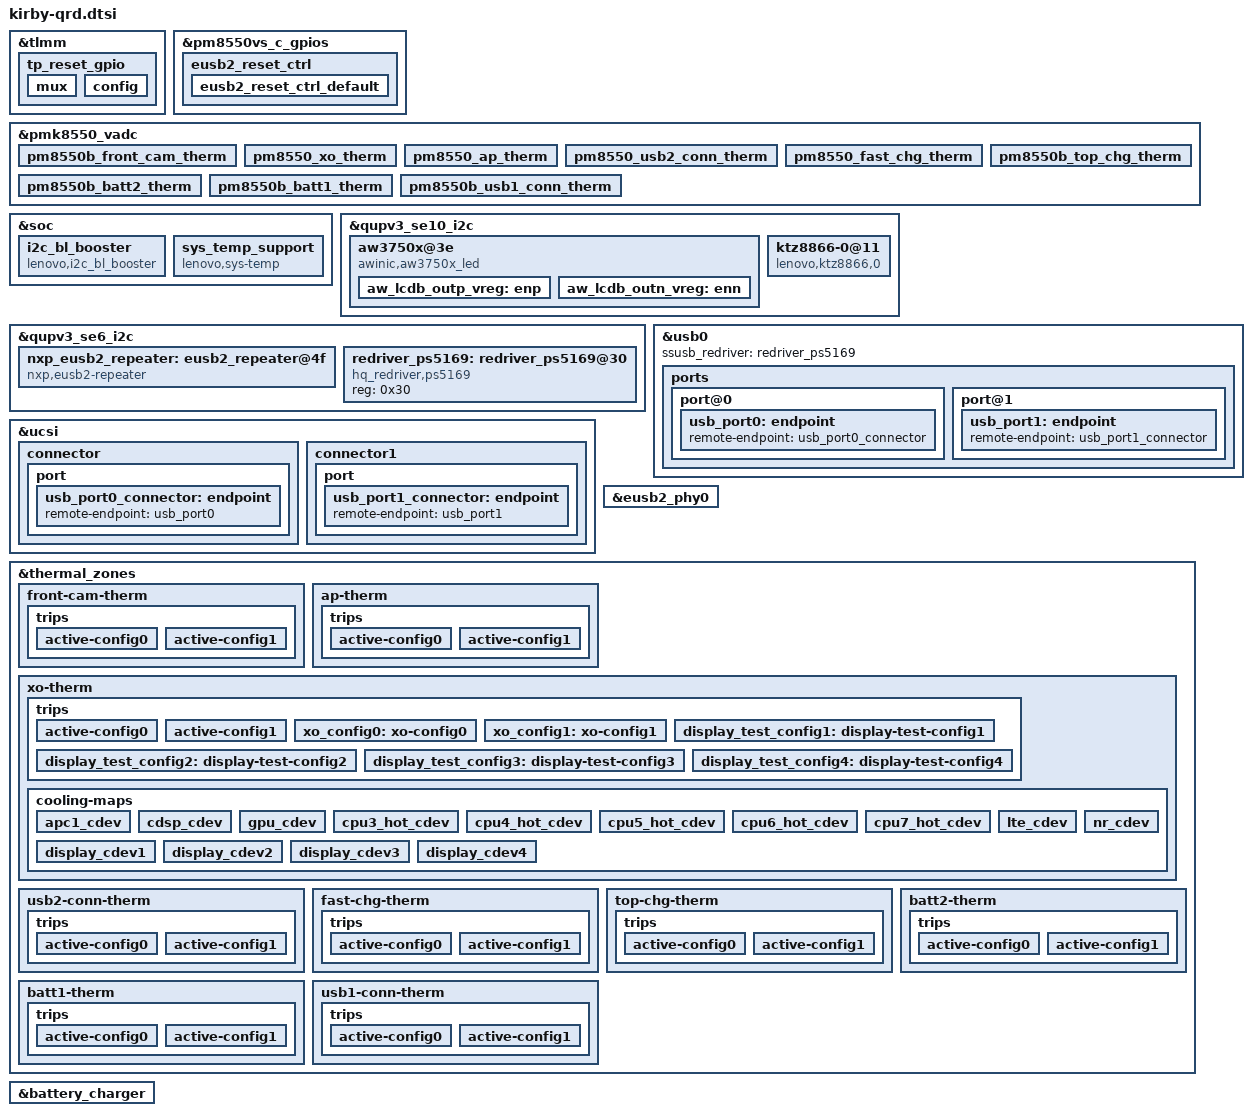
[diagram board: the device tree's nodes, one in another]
#include "pineapple-qrd.dtsi"
#include "kirby-touch-novatek.dtsi"

&tlmm {
	tp_reset_gpio: tp_reset_gpio {
		mux {
			pins = "gpio161";
			function = "gpio";
		};

		config {
			pins = "gpio161";
			bias-pull-up;
		};
	};
};

&pm8550vs_c_gpios {
	eusb2_reset_ctrl {
		eusb2_reset_ctrl_default: eusb2_reset_ctrl_default {
			pins = "gpio4";
			function = "normal";
			input-enable;
			output-enable;
			bias-disable;
			power-source = <1>;
			qcom,drive-strength = <2>;
		};
	};
};

&pmk8550_vadc {
	pm8550b_front_cam_therm {
		reg = <0x74c>;
		label = "pm8550b_front_cam_therm";
		qcom,ratiometric;
		qcom,hw-settle-time = <200>;
		qcom,pre-scaling = <1 1>;
		qcom,adc-tm-type = <1>;
	};

	pm8550_xo_therm {
		reg = <0x14a>;
		label = "pm8550_xo_therm";
		qcom,ratiometric;
		qcom,hw-settle-time = <200>;
		qcom,pre-scaling = <1 1>;
		qcom,adc-tm-type = <1>;
	};

	pm8550_ap_therm {
		reg = <0x144>;
		label = "pm8550_ap_therm";
		qcom,ratiometric;
		qcom,hw-settle-time = <200>;
		qcom,pre-scaling = <1 1>;
		qcom,adc-tm-type = <1>;
	};

	pm8550_usb2_conn_therm {
		reg = <0x147>;
		label = "pm8550_usb2_conn_therm";
		qcom,ratiometric;
		qcom,hw-settle-time = <200>;
		qcom,pre-scaling = <1 1>;
		qcom,adc-tm-type = <1>;
	};

	pm8550_fast_chg_therm {
		reg = <0x14d>;
		label = "pm8550_fast_chg_therm";
		qcom,ratiometric;
		qcom,hw-settle-time = <200>;
		qcom,pre-scaling = <1 1>;
		qcom,adc-tm-type = <1>;
	};

	pm8550b_top_chg_therm {
		reg = <0x749>;
		label = "pm8550b_top_chg_therm";
		qcom,ratiometric;
		qcom,pre-scaling = <1 1>;
		qcom,adc-tm-type = <1>;
	};

	pm8550b_batt2_therm {
		reg = <0x74d>;
		label = "pm8550b_batt2_therm";
		qcom,ratiometric;
		qcom,pre-scaling = <1 1>;
		qcom,adc-tm-type = <1>;
	};

	pm8550b_batt1_therm {
		reg = <0x744>;
		label = "pm8550b_batt1_therm";
		qcom,ratiometric;
		qcom,pre-scaling = <1 1>;
		qcom,adc-tm-type = <1>;
	};

	pm8550b_usb1_conn_therm {
		reg = <0x747>;
		label = "pm8550b_usb1_conn_therm";
		qcom,ratiometric;
		qcom,pre-scaling = <1 1>;
		qcom,adc-tm-type = <1>;
	};
};

&soc {
	i2c_bl_booster {
		compatible = "lenovo,i2c_bl_booster";
		num-dev = <1>;
		part-number = "ktz8866";
		bl-bw = [00 0b];
		bl-min-lvl = [00 00];
		bl-max-lvl = [07 ff];
		bl-def-lvl = [04 03];
		bl-lsb-mask = [0f];
		bl-msb-mask = [ff];
		status = "ok";
	};

	sys_temp_support {
		compatible = "lenovo,sys-temp";
		lenovo,temperature-names = "front_temp", "back_temp", "user_temp",
					   "user_front_temp", "user_back_temp", "hbm_temp";
		lenovo,sensor-listener-names = "front-cam-therm", "quiet-therm",
					       "usb2-conn-therm", "cam-flash-therm",
					       "batt1-therm", "usb1-conn-therm", "cpuss-0";
	};
};

&qupv3_se10_i2c {
	#address-cells = <1>;
	#size-cells = <0>;
	status = "ok";

	aw3750x@3e {
		compatible = "awinic,aw3750x_led";
		aw3750x_gpio_ctrl = <0>;
		reg = <0x3e>;
		limit = <370>;
		outp = <18>;
		outn = <18>;
		enn-gpio = <&tlmm 73 GPIO_ACTIVE_HIGH>;
		enp-gpio = <&tlmm 72 GPIO_ACTIVE_HIGH>;

		aw_lcdb_outp_vreg: enp {
			label = "outp";
			regulator-name = "outp";
			regulator-min-microvolt = <4000000>;
			regulator-max-microvolt = <6000000>;
		};

		aw_lcdb_outn_vreg: enn {
			label = "outn";
			regulator-name = "outn";
			regulator-min-microvolt = <4000000>;
			regulator-max-microvolt = <6000000>;
		};
	};

	ktz8866-0@11 {
		compatible = "lenovo,ktz8866,0";
		reg = <0x11>;
		hwen-gpio = <&tlmm 87 GPIO_ACTIVE_HIGH>;
		init-cmds = <0x07 0x00 0x01 0x00 0x2710
			     0x02 0x02 0xda 0xff 0x00
			     0x02 0x11 0x37 0xff 0x00
			     0x02 0x15 0x68 0xff 0x00
			     0x02 0x08 0x4f 0xff 0x00>;
		bl-cmds = <0x04 0x04 0x07 0x07 0x00
			   0x05 0x05 0xff 0xff 0x00>;
		enable-bl-cmds = <0x02 0x08 0x4f 0xff 0x00>;
		disable-bl-cmds = <0x02 0x08 0x00 0xff 0x00>;
		hbm-levels = <104 200 240>;
		status = "ok";
	};
};

&qupv3_se6_i2c {
	status = "ok";
	#address-cells = <1>;
	#size-cells = <0>;

	nxp_eusb2_repeater: eusb2_repeater@4f {
		status = "ok";
		compatible = "nxp,eusb2-repeater";
		reg = <0x4f>;
		vdd18-supply = <&pm_humu_l15>;
		vdd3-supply = <&pm_humu_l5>;
		reset-gpio = <&pm8550vs_c_gpios 4 GPIO_ACTIVE_HIGH>;
		pinctrl-names = "default";
		pinctrl-0 = <&eusb2_reset_ctrl_default>;
		qcom,param-override-seq-c1 = <0x40 0x06 0x22 0x07 0x65 0x08 0x03 0x0a>;
	};

	redriver_ps5169: redriver_ps5169@30 {
		status = "ok";
		compatible = "hq_redriver,ps5169";
		reg = <0x30>;
	};
};

&usb0 {
	ssusb_redriver = <&redriver_ps5169>;

	ports {
		port@0 {
			usb_port0: endpoint {
				remote-endpoint = <&usb_port0_connector>;
			};
		};

		port@1 {
			usb_port1: endpoint {
				remote-endpoint = <&usb_port1_connector>;
			};
		};
	};
};

&ucsi {
	connector {
		port {
			usb_port0_connector: endpoint {
				remote-endpoint = <&usb_port0>;
			};
		};
	};

	connector1 {
		port {
			usb_port1_connector: endpoint {
				remote-endpoint = <&usb_port1>;
			};
		};
	};
};

&eusb2_phy0 {
	dummy-supply = <&nxp_eusb2_repeater>;
	usb-repeater = <&nxp_eusb2_repeater>;
};

&thermal_zones {
	front-cam-therm {
		polling-delay-passive = <0>;
		polling-delay = <0>;
		thermal-sensors = <&pmk8550_vadc 0x74c>;

		trips {
			active-config0 {
				temperature = <125000>;
				hysteresis = <1000>;
				type = "passive";
			};

			active-config1 {
				temperature = <125000>;
				hysteresis = <1000>;
				type = "passive";
			};
		};
	};

	ap-therm {
		polling-delay-passive = <0>;
		polling-delay = <0>;
		thermal-sensors = <&pmk8550_vadc 0x144>;

		trips {
			active-config0 {
				temperature = <125000>;
				hysteresis = <1000>;
				type = "passive";
			};

			active-config1 {
				temperature = <125000>;
				hysteresis = <1000>;
				type = "passive";
			};
		};
	};

	xo-therm {
		polling-delay-passive = <0>;
		polling-delay = <0>;
		thermal-sensors = <&pmk8550_vadc 0x14a>;

		trips {
			active-config0 {
				temperature = <125000>;
				hysteresis = <1000>;
				type = "passive";
			};

			active-config1 {
				temperature = <125000>;
				hysteresis = <1000>;
				type = "passive";
			};

			xo_config0: xo-config0 {
				temperature = <78000>;
				hysteresis = <8000>;
				type = "passive";
			};

			xo_config1: xo-config1 {
				temperature = <80000>;
				hysteresis = <10000>;
				type = "passive";
			};

			display_test_config1: display-test-config1 {
				temperature = <125000>;
				hysteresis = <1000>;
				type = "passive";
			};

			display_test_config2: display-test-config2 {
				temperature = <125000>;
				hysteresis = <1000>;
				type = "passive";
			};

			display_test_config3: display-test-config3 {
				temperature = <125000>;
				hysteresis = <1000>;
				type = "passive";
			};

			display_test_config4: display-test-config4 {
				temperature = <125000>;
				hysteresis = <1000>;
				type = "passive";
			};
		};

		cooling-maps {
			apc1_cdev {
				trip = <&xo_config0>;
				cooling-device = <&APC1_pause 1 1>;
			};

			cdsp_cdev {
				trip = <&xo_config0>;
				cooling-device = <&cdsp_sw 5 0xffffffff>;
			};

			gpu_cdev {
				trip = <&xo_config0>;
				cooling-device = <&msm_gpu 5 0xffffffff>;
			};

			cpu3_hot_cdev {
				trip = <&xo_config1>;
				cooling-device = <&cpu3_hotplug 1 1>;
			};

			cpu4_hot_cdev {
				trip = <&xo_config1>;
				cooling-device = <&cpu4_hotplug 1 1>;
			};

			cpu5_hot_cdev {
				trip = <&xo_config1>;
				cooling-device = <&cpu5_hotplug 1 1>;
			};

			cpu6_hot_cdev {
				trip = <&xo_config1>;
				cooling-device = <&cpu6_hotplug 1 1>;
			};

			cpu7_hot_cdev {
				trip = <&xo_config1>;
				cooling-device = <&cpu7_hotplug 1 1>;
			};

			lte_cdev {
				trip = <&xo_config1>;
				cooling-device = <&modem_lte_dsc 0xff 0xff>;
			};

			nr_cdev {
				trip = <&xo_config1>;
				cooling-device = <&modem_nr_scg_dsc 0xff 0xff>;
			};

			display_cdev1 {
				trip = <&display_test_config1>;
				cooling-device = <&display_fps 1 1>;
			};

			display_cdev2 {
				trip = <&display_test_config2>;
				cooling-device = <&display_fps 2 2>;
			};

			display_cdev3 {
				trip = <&display_test_config3>;
				cooling-device = <&display_fps 3 3>;
			};

			display_cdev4 {
				trip = <&display_test_config4>;
				cooling-device = <&display_fps 4 4>;
			};
		};
	};

	usb2-conn-therm {
		polling-delay-passive = <0>;
		polling-delay = <0>;
		thermal-sensors = <&pmk8550_vadc 0x147>;

		trips {
			active-config0 {
				temperature = <125000>;
				hysteresis = <1000>;
				type = "passive";
			};

			active-config1 {
				temperature = <125000>;
				hysteresis = <1000>;
				type = "passive";
			};
		};
	};

	fast-chg-therm {
		polling-delay-passive = <0>;
		polling-delay = <0>;
		thermal-sensors = <&pmk8550_vadc 0x14d>;

		trips {
			active-config0 {
				temperature = <125000>;
				hysteresis = <1000>;
				type = "passive";
			};

			active-config1 {
				temperature = <125000>;
				hysteresis = <1000>;
				type = "passive";
			};
		};
	};

	top-chg-therm {
		polling-delay-passive = <0>;
		polling-delay = <0>;
		thermal-sensors = <&pmk8550_vadc 0x749>;

		trips {
			active-config0 {
				temperature = <125000>;
				hysteresis = <1000>;
				type = "passive";
			};

			active-config1 {
				temperature = <125000>;
				hysteresis = <1000>;
				type = "passive";
			};
		};
	};

	batt2-therm {
		polling-delay-passive = <0>;
		polling-delay = <0>;
		thermal-sensors = <&pmk8550_vadc 0x74d>;

		trips {
			active-config0 {
				temperature = <125000>;
				hysteresis = <1000>;
				type = "passive";
			};

			active-config1 {
				temperature = <125000>;
				hysteresis = <1000>;
				type = "passive";
			};
		};
	};

	batt1-therm {
		polling-delay-passive = <0>;
		polling-delay = <0>;
		thermal-sensors = <&pmk8550_vadc 0x744>;

		trips {
			active-config0 {
				temperature = <125000>;
				hysteresis = <1000>;
				type = "passive";
			};

			active-config1 {
				temperature = <125000>;
				hysteresis = <1000>;
				type = "passive";
			};
		};
	};

	usb1-conn-therm {
		polling-delay-passive = <0>;
		polling-delay = <0>;
		thermal-sensors = <&pmk8550_vadc 0x747>;

		trips {
			active-config0 {
				temperature = <125000>;
				hysteresis = <1000>;
				type = "passive";
			};

			active-config1 {
				temperature = <125000>;
				hysteresis = <1000>;
				type = "passive";
			};
		};
	};
};

&battery_charger {
	qcom,wireless-fw-name = "idt9418.bin";
	qcom,thermal-mitigation = <11800000 10500000 10000000 9500000
				   9000000 8500000 8000000 7000000
				   6000000 3000000 2000000 500000>;
	#cooling-cells = <2>;
};

